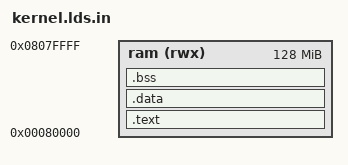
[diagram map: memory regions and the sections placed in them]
/*
 * BonsaiOS Kernel Linker Script
 */

OUTPUT_FORMAT("elf64-littleaarch64")
OUTPUT_ARCH(aarch64)
ENTRY(_start)

MEMORY
{
    /* Orin's RAM starts at a high address, but for loading, we use a lower identity-mapped address. */
    /* The bootloader will place us at 0x80000. */
    ram (rwx) : ORIGIN = 0x80000, LENGTH = 128M
}

SECTIONS
{
    /* The kernel's code and read-only data */
    .text :
    {
        . = ORIGIN(ram);
        KEEP(*(.text.boot))
        *(.text)
        *(.text.*)
        *(.rodata)
        *(.rodata.*)
    } >ram

    /* Writable data */
    .data :
    {
        . = ALIGN(4K);
        *(.data)
        *(.data.*)
    } >ram

    /* Uninitialized data (BSS) */
    .bss :
    {
        . = ALIGN(4K);
        __bss_start = .;
        *(.bss)
        *(.bss.*)
        __bss_end = .;
    } >ram

    . = ALIGN(4K);
    _end = .;

    /DISCARD/ :
    {
        *(.comment)
        *(.eh_frame)
        *(.note.gnu.build-id)
    }
}
